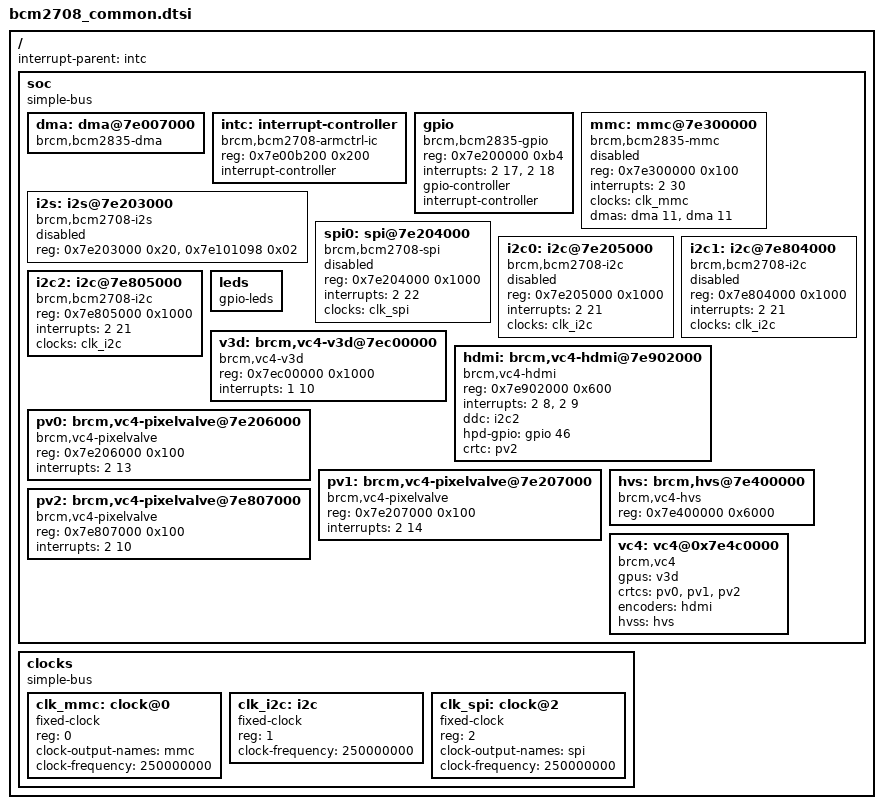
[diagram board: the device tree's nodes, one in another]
/include/ "skeleton.dtsi"

/ {
	interrupt-parent = <&intc>;

	soc: soc {
		compatible = "simple-bus";
		#address-cells = <1>;
		#size-cells = <1>;

		dma: dma@7e007000 {
			compatible = "brcm,bcm2835-dma";
			#dma-cells = <1>;
		};

		intc: interrupt-controller {
			compatible = "brcm,bcm2708-armctrl-ic";
			reg = <0x7e00b200 0x200>;
			interrupt-controller;
			#interrupt-cells = <2>;
		};

		gpio: gpio {
			compatible = "brcm,bcm2835-gpio";
			reg = <0x7e200000 0xb4>;
			interrupts = <2 17>, <2 18>;

			gpio-controller;
			#gpio-cells = <2>;

			interrupt-controller;
			#interrupt-cells = <2>;
		};

		mmc: mmc@7e300000 {
			compatible = "brcm,bcm2835-mmc";
			reg = <0x7e300000 0x100>;
			interrupts = <2 30>;
			clocks = <&clk_mmc>;
			dmas = <&dma 11>,
			       <&dma 11>;
			dma-names = "tx", "rx";
			status = "disabled";
		};

		i2s: i2s@7e203000 {
			compatible = "brcm,bcm2708-i2s";
			reg = <0x7e203000 0x20>,
			      <0x7e101098 0x02>;

			//dmas = <&dma 2>,
			//       <&dma 3>;
			dma-names = "tx", "rx";
			status = "disabled";
		};

		spi0: spi@7e204000 {
			compatible = "brcm,bcm2708-spi";
			reg = <0x7e204000 0x1000>;
			interrupts = <2 22>;
			clocks = <&clk_spi>;
			#address-cells = <1>;
			#size-cells = <0>;
			status = "disabled";
		};

		i2c0: i2c@7e205000 {
			compatible = "brcm,bcm2708-i2c";
			reg = <0x7e205000 0x1000>;
			interrupts = <2 21>;
			clocks = <&clk_i2c>;
			#address-cells = <1>;
			#size-cells = <0>;
			status = "disabled";
		};

		i2c1: i2c@7e804000 {
			compatible = "brcm,bcm2708-i2c";
			reg = <0x7e804000 0x1000>;
			interrupts = <2 21>;
			clocks = <&clk_i2c>;
			#address-cells = <1>;
			#size-cells = <0>;
			status = "disabled";
		};

		i2c2: i2c@7e805000 {
			compatible = "brcm,bcm2708-i2c";
			reg = <0x7e805000 0x1000>;
			interrupts = <2 21>;
			clocks = <&clk_i2c>;
			#address-cells = <1>;
			#size-cells = <0>;
		};

		leds: leds {
			compatible = "gpio-leds";
		};

		v3d: brcm,vc4-v3d@7ec00000 {
			compatible = "brcm,vc4-v3d";
			reg = <0x7ec00000 0x1000>;
			interrupts = <1 10>;
		};

		hdmi: brcm,vc4-hdmi@7e902000 {
			compatible = "brcm,vc4-hdmi";
			reg = <0x7e902000 0x600>;
			interrupts = <2 8>, <2 9>;
			ddc = <&i2c2>;
			hpd-gpio = <&gpio 46 0>;
			crtc = <&pv2>;
		};

		pv0: brcm,vc4-pixelvalve@7e206000 {
			compatible = "brcm,vc4-pixelvalve";
			reg = <0x7e206000 0x100>;
			interrupts = <2 13>; /* pwa2 */
		};

		pv1: brcm,vc4-pixelvalve@7e207000 {
			compatible = "brcm,vc4-pixelvalve";
			reg = <0x7e207000 0x100>;
			interrupts = <2 14>; /* pwa1 */
		};

		pv2: brcm,vc4-pixelvalve@7e807000 {
			compatible = "brcm,vc4-pixelvalve";
			reg = <0x7e807000 0x100>;
			interrupts = <2 10>; /* pixelvalve */
		};

		hvs: brcm,hvs@7e400000 {
			compatible = "brcm,vc4-hvs";
			reg = <0x7e400000 0x6000>;
		};

		vc4: vc4@0x7e4c0000 {
			compatible = "brcm,vc4";

			gpus = <&v3d>;
			crtcs = <&pv0>, <&pv1>, <&pv2>;
			encoders = <&hdmi>;
			hvss = <&hvs>;
		};
	};

	clocks {
		compatible = "simple-bus";
		#address-cells = <1>;
		#size-cells = <0>;

		clk_mmc: clock@0 {
			compatible = "fixed-clock";
			reg = <0>;
			#clock-cells = <0>;
			clock-output-names = "mmc";
			clock-frequency = <250000000>;
		};

		clk_i2c: i2c {
			compatible = "fixed-clock";
			reg = <1>;
			#clock-cells = <0>;
			clock-frequency = <250000000>;
		};

		clk_spi: clock@2 {
			compatible = "fixed-clock";
			reg = <2>;
			#clock-cells = <0>;
			clock-output-names = "spi";
			clock-frequency = <250000000>;
		};
	};
};
